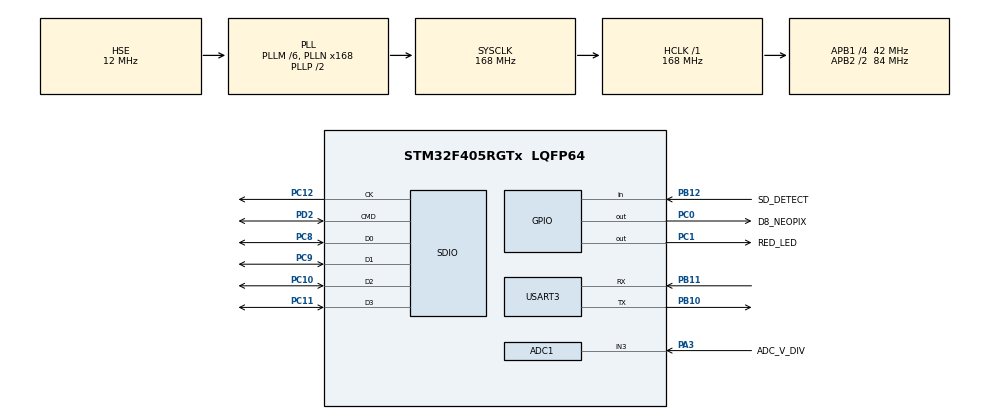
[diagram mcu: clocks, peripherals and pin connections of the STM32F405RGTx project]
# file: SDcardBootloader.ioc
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ADC1.Channel-0\#ChannelRegularConversion=ADC_CHANNEL_3
ADC1.NbrOfConversionFlag=1
ADC1.Rank-0\#ChannelRegularConversion=1
ADC1.SamplingTime-0\#ChannelRegularConversion=ADC_SAMPLETIME_3CYCLES
ADC1.master=1
Dma.Request0=SDIO_RX
Dma.Request1=SDIO_TX
Dma.SDIO_RX.0.Direction=DMA_PERIPH_TO_MEMORY
Dma.SDIO_RX.0.FIFOMode=DMA_FIFOMODE_ENABLE
Dma.SDIO_RX.0.FIFOThreshold=DMA_FIFO_THRESHOLD_FULL
Dma.SDIO_RX.0.Instance=DMA2_Stream3
Dma.SDIO_RX.0.MemBurst=DMA_MBURST_INC4
Dma.SDIO_RX.0.MemDataAlignment=DMA_MDATAALIGN_WORD
Dma.SDIO_RX.0.MemInc=DMA_MINC_ENABLE
Dma.SDIO_RX.0.Mode=DMA_PFCTRL
Dma.SDIO_RX.0.PeriphBurst=DMA_PBURST_INC4
Dma.SDIO_RX.0.PeriphDataAlignment=DMA_PDATAALIGN_WORD
Dma.SDIO_RX.0.PeriphInc=DMA_PINC_DISABLE
Dma.SDIO_RX.0.Priority=DMA_PRIORITY_LOW
Dma.SDIO_TX.1.Direction=DMA_MEMORY_TO_PERIPH
Dma.SDIO_TX.1.FIFOMode=DMA_FIFOMODE_ENABLE
Dma.SDIO_TX.1.FIFOThreshold=DMA_FIFO_THRESHOLD_FULL
Dma.SDIO_TX.1.Instance=DMA2_Stream6
Dma.SDIO_TX.1.MemBurst=DMA_MBURST_INC4
Dma.SDIO_TX.1.MemDataAlignment=DMA_MDATAALIGN_WORD
Dma.SDIO_TX.1.MemInc=DMA_MINC_ENABLE
Dma.SDIO_TX.1.Mode=DMA_PFCTRL
Dma.SDIO_TX.1.PeriphBurst=DMA_PBURST_INC4
Dma.SDIO_TX.1.PeriphDataAlignment=DMA_PDATAALIGN_WORD
Dma.SDIO_TX.1.PeriphInc=DMA_PINC_DISABLE
Dma.SDIO_TX.1.Priority=DMA_PRIORITY_LOW
FATFS.BSP.number=1
FATFS.USE_DMA_CODE_SD=1
FATFS._MAX_SS=4096
FATFS._MIN_SS=512
FATFS._USE_LFN=2
FATFS0.BSP.STBoard=false
FATFS0.BSP.api=Unknown
FATFS0.BSP.instance=PB12
FATFS0.BSP.ip=GPIO
FATFS0.BSP.mode=Input
FATFS0.BSP.name=Detect_SDIO
FATFS0.BSP.solution=PB12
Mcu.Family=STM32F4
Mcu.Name=STM32F405RGTx
Mcu.Package=LQFP64
NVIC.DMA2_Stream3_IRQn=true\:0\:0\:false\:false\:true\:false\:true\:true
NVIC.DMA2_Stream6_IRQn=true\:0\:0\:false\:false\:true\:false\:true\:true
NVIC.PriorityGroup=NVIC_PRIORITYGROUP_4
NVIC.SDIO_IRQn=true\:0\:0\:false\:false\:true\:true\:true\:true
PA13.Mode=Serial_Wire
PA13.Signal=SYS_JTMS-SWDIO
PA14.Mode=Serial_Wire
PA14.Signal=SYS_JTCK-SWCLK
PA3.GPIO_Label=ADC_V_DIV
PA3.Signal=ADCx_IN3
PB10.Mode=Asynchronous
PB10.Signal=USART3_TX
PB11.Mode=Asynchronous
PB11.Signal=USART3_RX
PB12.GPIO_Label=SD_DETECT
PB12.GPIO_PuPd=GPIO_PULLUP
PB12.Signal=GPIO_Input
PC0.GPIO_Label=D8_NEOPIX
PC0.Signal=GPIO_Output
PC1.GPIO_Label=RED_LED
PC1.Signal=GPIO_Output
PC10.GPIO_PuPd=GPIO_PULLUP
PC10.Mode=SD_4_bits_Wide_bus
PC10.Signal=SDIO_D2
PC11.GPIO_PuPd=GPIO_NOPULL
PC11.Mode=SD_4_bits_Wide_bus
PC11.Signal=SDIO_D3
PC12.GPIO_PuPd=GPIO_NOPULL
PC12.Mode=SD_4_bits_Wide_bus
PC12.Signal=SDIO_CK
PC8.GPIO_PuPd=GPIO_PULLUP
PC8.Mode=SD_4_bits_Wide_bus
PC8.Signal=SDIO_D0
PC9.GPIO_PuPd=GPIO_PULLUP
PC9.Mode=SD_4_bits_Wide_bus
PC9.Signal=SDIO_D1
PD2.GPIO_PuPd=GPIO_PULLUP
PD2.Mode=SD_4_bits_Wide_bus
PD2.Signal=SDIO_CMD
PH0-OSC_IN.Mode=HSE-External-Oscillator
PH0-OSC_IN.Signal=RCC_OSC_IN
PH1-OSC_OUT.Mode=HSE-External-Oscillator
PH1-OSC_OUT.Signal=RCC_OSC_OUT
ProjectManager.HeapSize=0x2000
ProjectManager.StackSize=0x4000
ProjectManager.TargetToolchain=STM32CubeIDE
RCC.48MHZClocksFreq_Value=48000000
RCC.AHBFreq_Value=168000000
RCC.APB1CLKDivider=RCC_HCLK_DIV4
RCC.APB1Freq_Value=42000000
RCC.APB1TimFreq_Value=84000000
RCC.APB2CLKDivider=RCC_HCLK_DIV2
RCC.APB2Freq_Value=84000000
RCC.APB2TimFreq_Value=168000000
RCC.CortexFreq_Value=168000000
RCC.HCLKFreq_Value=168000000
RCC.HSE_VALUE=12000000
RCC.HSI_VALUE=16000000
RCC.LSE_VALUE=32768
RCC.PLLM=6
RCC.PLLN=168
RCC.PLLQ=7
RCC.PLLSourceVirtual=RCC_PLLSOURCE_HSE
RCC.SYSCLKFreq_VALUE=168000000
RCC.SYSCLKSource=RCC_SYSCLKSOURCE_PLLCLK
RCC.VCOOutputFreq_Value=336000000
SDIO.ClockDiv=4
SH.ADCx_IN3.0=ADC1_IN3,IN3
USART3.VirtualMode=VM_ASYNC
VP_FATFS_VS_SDIO.Mode=SDIO
board=custom

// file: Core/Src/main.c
/* USER CODE BEGIN Header */
/**
  ******************************************************************************
  * @file           : main.c
  * @brief          : Main program body
  ******************************************************************************
  * @attention
  *
  * Copyright (c) 2023 STMicroelectronics.
  * All rights reserved.
  *
  * This software is licensed under terms that can be found in the LICENSE file
  * in the root directory of this software component.
  * If no LICENSE file comes with this software, it is provided AS-IS.
  *
  ******************************************************************************
  */
/* USER CODE END Header */
#include "main.h"
#include "adc.h"
#include "dma.h"
#include "fatfs.h"
#include "sdio.h"
#include "usart.h"
#include "gpio.h"

/* USER CODE BEGIN Includes */
#include "bootloaderMain.h"
/* USER CODE END Includes */

void SystemClock_Config(void);

int main(void)
{

  /* MCU Configuration--------------------------------------------------------*/

  /* Reset of all peripherals, Initializes the Flash interface and the Systick. */
  HAL_Init();

  /* Configure the system clock */
  SystemClock_Config();

  /* Initialize all configured peripherals */
  MX_GPIO_Init();
  MX_DMA_Init();
  MX_ADC1_Init();
  MX_SDIO_SD_Init();
  MX_FATFS_Init();
  MX_USART3_UART_Init();

  /* Infinite loop */
  /* USER CODE BEGIN WHILE */
  while (1)
  {
	  if(isthereSDcard()==YES){
		  if(isThereFirmwarefile()==YES){
			  if(doFlashandSDfirmwarecontentsMatch()==YES){
				  jumpToApp();
			  }else{
				  eraseFLASHappSpace();
				  programfromRAMtoFLASH();
				  jumpToApp();
			  }
		  }
	  }
	  HAL_Delay(100);
    /* USER CODE END WHILE */

  }
}

void SystemClock_Config(void)
{
  RCC_OscInitTypeDef RCC_OscInitStruct = {0};
  RCC_ClkInitTypeDef RCC_ClkInitStruct = {0};

  /** Configure the main internal regulator output voltage
  */
  __HAL_RCC_PWR_CLK_ENABLE();
  __HAL_PWR_VOLTAGESCALING_CONFIG(PWR_REGULATOR_VOLTAGE_SCALE1);

  /** Initializes the RCC Oscillators according to the specified parameters
  * in the RCC_OscInitTypeDef structure.
  */
  RCC_OscInitStruct.OscillatorType = RCC_OSCILLATORTYPE_HSE;
  RCC_OscInitStruct.HSEState = RCC_HSE_ON;
  RCC_OscInitStruct.PLL.PLLState = RCC_PLL_ON;
  RCC_OscInitStruct.PLL.PLLSource = RCC_PLLSOURCE_HSE;
  RCC_OscInitStruct.PLL.PLLM = 6;
  RCC_OscInitStruct.PLL.PLLN = 168;
  RCC_OscInitStruct.PLL.PLLP = RCC_PLLP_DIV2;
  RCC_OscInitStruct.PLL.PLLQ = 7;
  if (HAL_RCC_OscConfig(&RCC_OscInitStruct) != HAL_OK)
  {
    Error_Handler();
  }

  /** Initializes the CPU, AHB and APB buses clocks
  */
  RCC_ClkInitStruct.ClockType = RCC_CLOCKTYPE_HCLK|RCC_CLOCKTYPE_SYSCLK
                              |RCC_CLOCKTYPE_PCLK1|RCC_CLOCKTYPE_PCLK2;
  RCC_ClkInitStruct.SYSCLKSource = RCC_SYSCLKSOURCE_PLLCLK;
  RCC_ClkInitStruct.AHBCLKDivider = RCC_SYSCLK_DIV1;
  RCC_ClkInitStruct.APB1CLKDivider = RCC_HCLK_DIV4;
  RCC_ClkInitStruct.APB2CLKDivider = RCC_HCLK_DIV2;

  if (HAL_RCC_ClockConfig(&RCC_ClkInitStruct, FLASH_LATENCY_5) != HAL_OK)
  {
    Error_Handler();
  }
}

void Error_Handler(void)
{
  __disable_irq();
  while (1)
  {
  }
}
